# tviic2d6mddr register map
Vendor: Cypress Semiconductor; Series: tviic2d6mddr; File version: 1.0
CPU: CM7 r0p1, little endian, MPU, FPU, VTOR, 3 interrupt priority bits
Registers are 32-bit, read-write, reset 0x0 unless marked. A register's access mark holds for its fields unless they carry their own. Offsets are from the block's base; [hi:lo] are bit positions; lines under a group give offsets from that group; 'fields as' and 'values as' point back to an identical list.

## VIDEOSS0 (part 13 of 18) — Video and Graphics Subsystem IP
Base 0x40A00000
0x80000 VIDEOIO group — Video I/O Core
  0x24000 DISENG1 group — Display Engine
    0x1400 HISTOGRAM1 group — Histogram Unit
      0x08 BINCNTTHRESH — Bin counter threshold value.
        [28:0] BINCNT_THRESH — Bin counters below this threshold will be reported as 0. This threshold value will also affect the BINCNT_ACCU mode where 0 will be added for all bin counters below the threshold. (format is unsigned integer)
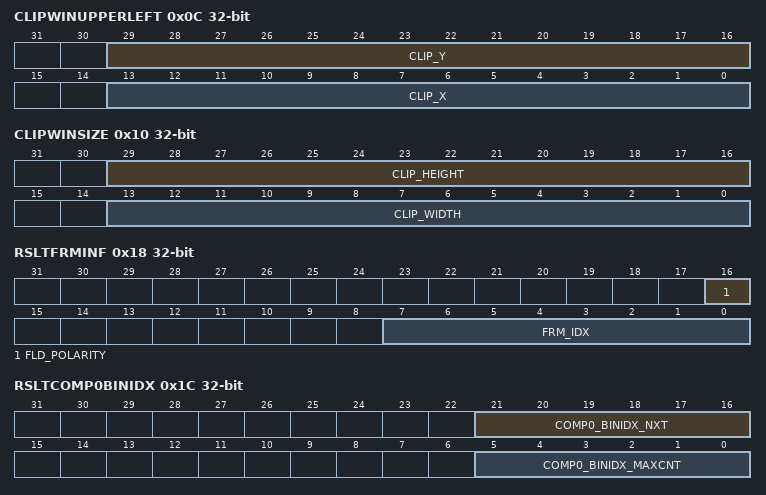
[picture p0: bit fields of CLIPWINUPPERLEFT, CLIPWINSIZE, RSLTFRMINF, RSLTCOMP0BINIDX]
      0x0C CLIPWINUPPERLEFT — Coordinates of upper left corner of clip window.
        [29:16] CLIP_Y — Y coordinate of upper left corner of clip window. (format is unsigned integer)
        [13:0] CLIP_X — X coordinate of upper left corner of clip window. (format is unsigned integer)
      0x10 CLIPWINSIZE — Dimensions of clip window.
        [29:16] CLIP_HEIGHT — Height of clip window, given minus one. (format is unsigned integer)
        [13:0] CLIP_WIDTH — Width of clip window, given minus one. (format is unsigned integer)
      0x14 RSLTRDY ro — Measurement result status.
        [0] RSLT_RDY — A one indicates that measurement results (in registers Rslt...) are valid and can be read. (format is unsigned integer)
      0x18 RSLTFRMINF ro — Additional information on the measurement results.
        [16] FLD_POLARITY — Returns field polarity of the measured frame. This read value of this field is undefined in display stream context; use in storage, content or safety stream context only. (format is unsigned integer)
        [7:0] FRM_IDX — Each frame passing the histogram unit gets an index, which is the value of a wrapped around counter, which counts the frames independent from how the histogram unit is configured. The index of the frame of the ongoing readout can be read here. In display stream context, if the display operation ends (framegen is switched off and sequence complete occurs) this frame index is reset to 0. (format is unsigned integer)
      0x1C RSLTCOMP0BINIDX ro — Results of frame measurement for component 0.
        [21:16] COMP0_BINIDX_NXT — Do not use this filed. The index of the bin, that will be next accessed by register RsltComp0Bincnt. In the case of RGB pixels, component0 means the red value, in the case of YUV pixels, component 0 means the Y value. If luma/luminance calculation is switched on by field lum_mode component0 is the calculated luma/luminance. (format is unsigned integer)
        [5:0] COMP0_BINIDX_MAXCNT — The index of the bin of the component 0 histogram, which contains the highest counter value, which were read until now for the ongoing readout. In the case of RGB pixels, component 0 means the red value, in the case of YUV pixels, component0 means the Y value. If luma/luminance calculation is switched on by field lum_mode component0 is the calculated luma/luminance. (format is unsigned integer)
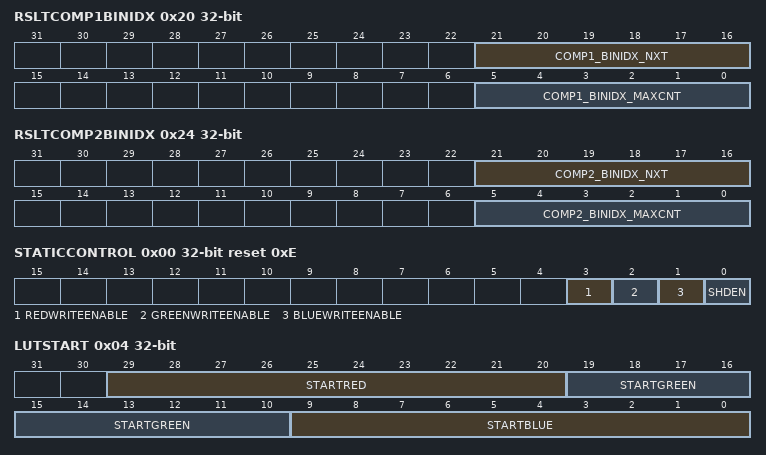
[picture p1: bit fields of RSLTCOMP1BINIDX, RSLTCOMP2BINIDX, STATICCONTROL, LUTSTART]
      0x20 RSLTCOMP1BINIDX ro — Results of frame measurement for component 1.
        [21:16] COMP1_BINIDX_NXT — The index of the bin, that will be next accessed by register RsltComp1Bincnt. In the case of RGB pixels, component 1 means the green value. In the case of YUV pixels, component 1 means the Cb value. (format is unsigned integer)
        [5:0] COMP1_BINIDX_MAXCNT — The index of the bin of the component 1 histogram, which contains the highest counter value, which were read until now for the ongoing readout. In the case of RGB pixels, component 1 means the green value. In the case of YUV pixels, component 1 means the Cb value. (format is unsigned integer)
      0x24 RSLTCOMP2BINIDX ro — Results of frame measurement for component 2.
        [21:16] COMP2_BINIDX_NXT — The index of the bin, that will be next accessed by register RsltComp2Bincnt. In the case of RGB pixels, component 2 means the blue value. In the case of YUV pixels, component 2 means the Cr value. (format is unsigned integer)
        [5:0] COMP2_BINIDX_MAXCNT — The index of the bin of the component 2 histogram, which contains the highest counter value, which were read until now for the ongoing readout. In the case of RGB pixels, component 2 means the blue value. In the case of YUV pixels, component 2 means the Cr value. (format is unsigned integer)
      0x28 RSLTCOMP0SUM ro — Sum of all component 0 values.
        [31:0] COMP0_SUM — Sum of all component 0 values. In the case of RGB pixels, component 0 means the red value, in the case of YUV pixels, component 0 means the Y value. If luma/luminance calculation is switched on by field lum_mode, component 0 is the calculated luma/luminance. If the read value is 0xFFFFFFFF a counter overflow has occurred and the read value should not be used (this can only happen for frame dimensions beyond 2^12 * 2^12). (format is unsigned integer)
      0x2C RSLTCOMP1SUM ro — Sum of all component 1 values.
        [31:0] COMP1_SUM — Sum of all component 1 values. In the case of RGB pixels, component 1 means the green value. In the case of YUV pixels, component 1 means the Cb value. If the read value is 0xFFFFFFFF a counter overflow has occurred and the read value should not be used (this can only happen for frame dimensions beyond 2^12 * 2^12). (format is unsigned integer)
      0x30 RSLTCOMP2SUM ro — Sum of all component 2 values.
        [31:0] COMP2_SUM — Sum of all component 2 values. In the case of RGB pixels, component 2 means the blue value. In the case of YUV pixels, component 2 means the Cr value. If the read value is 0xFFFFFFFF a counter overflow has occurred and the read value should not be used (this can only happen for frame dimensions beyond 2^12 * 2^12). (format is unsigned integer)
      0x34 RSLTCOMP0BINCNT ro — Bin counters of component 0 histogram. This register do NOT support debugger access followed by software access (they clear on read)
        [28:0] COMP0_BINCNT — Counter of current bin number in component 0 histogram. In the case of RGB pixels, component 0 means the red value, in the case of YUV pixels, component 0 means the Y value. (format is unsigned integer)
      0x38 RSLTCOMP1BINCNT ro — Bin counters of component 1 histogram. This register do NOT support debugger access followed by software access (they clear on read)
        [28:0] COMP1_BINCNT — Counter of current bin number in component 1 histogram. In the case of RGB pixels, component 1 means the green value. In the case of YUV pixels, component 1 means the Cb value. (format is unsigned integer)
      0x3C RSLTCOMP2BINCNT ro — Bin counters of component 2 histogram. This register do NOT support debugger access followed by software access (they clear on read)
        [28:0] COMP2_BINCNT — Counter of current bin index in component 2 histogram. In the case of RGB pixels, component 2 means the blue value. In the case of YUV pixels, component 2 means the Cb value. (format is unsigned integer)
      0x40 FRMSTRTTRIG wo reset not defined — Triggers for loading shadow registers and starting measurement with next input frame.
        [0] MSRMNT_STRT_TRIG — Writing value 1 into this field initiates the measurement of the next frame. (format is unsigned integer)
    0x1800 GAMMACOR21 group — Gamma Correction Unit 2
      0x00 STATICCONTROL reset 0xE — Static control settings.
        [3] REDWRITEENABLE — Write enable for the red color sampling point entries.
        [2] GREENWRITEENABLE — Write enable for the green color sampling point entries.
        [1] BLUEWRITEENABLE — Write enable for the blue color sampling point entries.
        [0] SHDEN — Enables shadowing of all RWS type registers (0=write_through, 1=shadowed).
      0x04 LUTSTART wo — Start values for look-up table programming.
        [29:20] STARTRED — Start value for red or luma (Y) channel. (format is unsigned integer)
        [19:10] STARTGREEN — Start value for green or chroma (U) channel. (format is unsigned integer)
        [9:0] STARTBLUE — Start value for blue or chroma (V) channel. (format is unsigned integer)
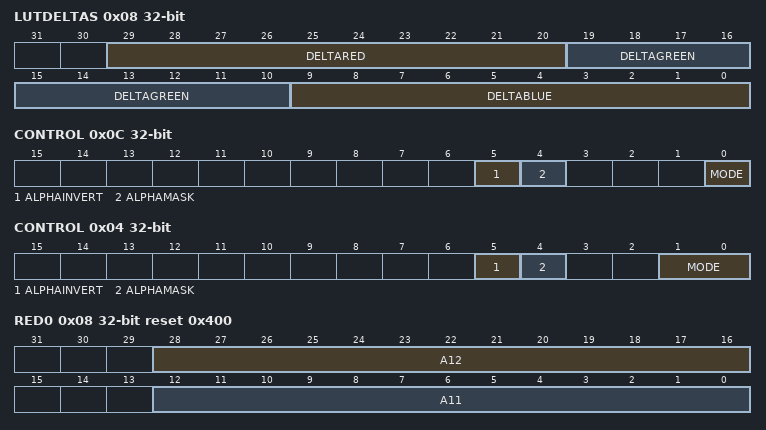
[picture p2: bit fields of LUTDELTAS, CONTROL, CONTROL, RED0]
      0x08 LUTDELTAS wo reset not defined — Delta values for look-up table programming.
        [29:20] DELTARED — Delta value for red or luma (Y) channel. (format is signed integer)
        [19:10] DELTAGREEN — Delta value for green or chroma (U) channel. (format is signed integer)
        [9:0] DELTABLUE — Delta value for blue or chroma (V) channel. (format is signed integer)
      0x0C CONTROL — Dynamic control settings.
        [5] ALPHAINVERT — Value 1 inverts the effect of the alpha mask mode when enabled (pixels with alpha value greater or equal 0.5 are by-passed).
        [4] ALPHAMASK — Value 1 enables the alpha mask mode. In this mode all pixels with an alpha value smaller than 0.5 are by-passed unchanged.
        [0] MODE — Operation mode for gamma correction unit
          0=NEUTRAL (Module in neutral mode, input data is bypassed to the output.); 1=GAMMACOR (Module in gamma correction mode.)
    0x1C00 MATRIX1 group — Color Matrix
      0x00 STATICCONTROL — Color Matrix static control register
        [0] SHDEN — Enables shadowing of all RWS type registers (0=write_through, 1=shadowed).
      0x04 CONTROL — Color Matrix control register
        [5] ALPHAINVERT — Value 1 inverts the effect of the alpha mask mode when enabled (pixels with alpha value greater or equal 0.5 are by-passed).
        [4] ALPHAMASK — Value 1 enables the alpha mask mode. In this mode all pixels with an alpha value smaller than 0.5 are by-passed unchanged.
        [1:0] MODE — Operation mode for color matrix
          0=NEUTRAL (Module in neutral mode, input data is bypassed); 1=MATRIX (Module in matrix mode, input data is multiplied with matrix values); 2=PREMUL (Module in alpha pre-multiplication mode, input color is multiplied with input alpha); 3=RSVD (N/A)
      0x08 RED0 reset 0x400 — Matrix values for calculation of the red output value.
        [28:16] A12 — Value for green input. (format is signed fix-point 3.10)
        [12:0] A11 — Value for red input. (format is signed fix-point 3.10)
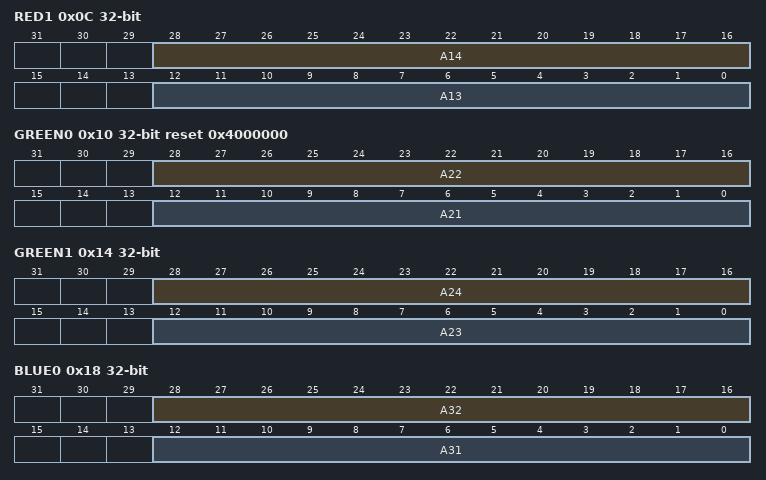
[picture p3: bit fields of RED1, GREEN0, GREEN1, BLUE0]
      0x0C RED1 — Matrix values for calculation of the red output value.
        [28:16] A14 — Value for alpha input. (format is signed fix-point 3.10)
        [12:0] A13 — Value for blue input. (format is signed fix-point 3.10)
      0x10 GREEN0 reset 0x4000000 — Matrix values for calculation of the green output value.
        [28:16] A22 — Value for green input. (format is signed fix-point 3.10)
        [12:0] A21 — Value for red input. (format is signed fix-point 3.10)
      0x14 GREEN1 — Matrix values for calculation of the green output value.
        [28:16] A24 — Value for alpha input. (format is signed fix-point 3.10)
        [12:0] A23 — Value for blue input. (format is signed fix-point 3.10)
      0x18 BLUE0 — Matrix values for calculation of the blue output value.
        [28:16] A32 — Value for green input. (format is signed fix-point 3.10)
        [12:0] A31 — Value for red input. (format is signed fix-point 3.10)
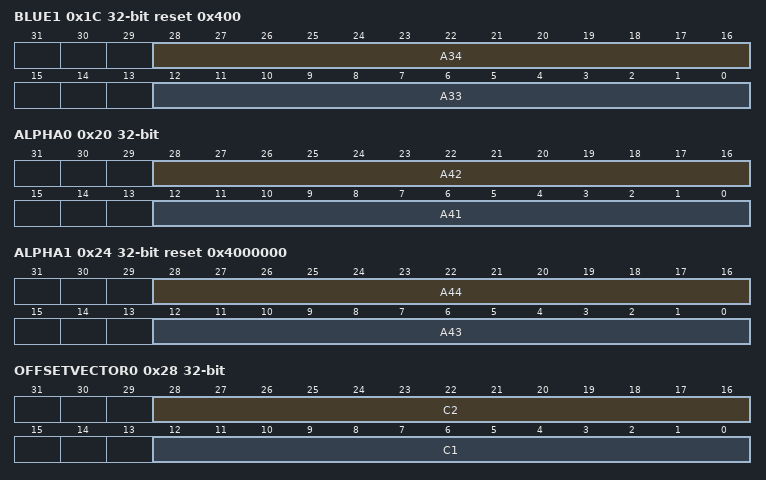
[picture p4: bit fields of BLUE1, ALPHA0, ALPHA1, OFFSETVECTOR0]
      0x1C BLUE1 reset 0x400 — Matrix values for calculation of the blue output value.
        [28:16] A34 — Value for alpha input. (format is signed fix-point 3.10)
        [12:0] A33 — Value for blue input. (format is signed fix-point 3.10)
      0x20 ALPHA0 — Matrix values for calculation of the alpha output value.
        [28:16] A42 — Value for green input. (format is signed fix-point 3.10)
        [12:0] A41 — Value for red input. (format is signed fix-point 3.10)
      0x24 ALPHA1 reset 0x4000000 — Matrix values for calculation of the alpha output value.
        [28:16] A44 — Value for alpha input. (format is signed fix-point 3.10)
        [12:0] A43 — Value for blue input. (format is signed fix-point 3.10)
      0x28 OFFSETVECTOR0 — Offset vectors for red and green output.
        [28:16] C2 — Green output offset. (format is signed integer)
        [12:0] C1 — Red output offset. (format is signed integer)
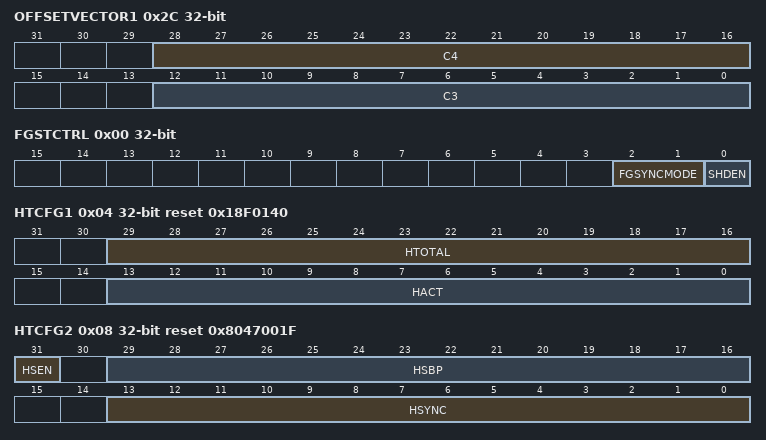
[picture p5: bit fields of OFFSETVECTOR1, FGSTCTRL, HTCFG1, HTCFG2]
      0x2C OFFSETVECTOR1 — Offset vectors for blue and alpha output.
        [28:16] C4 — Alpha output offset. Note that the 8-bit alpha input is up-scaled to 10-bit, before the matrix and this offset is applied, and down-scaled to 8-bit for output afterwards. (format is signed integer)
        [12:0] C3 — Blue output offset. (format is signed integer)
    0x2000 FRAMEGEN1 group — Frame Generator
      0x00 FGSTCTRL — FrameGen Static Control Register
        [2:1] FGSYNCMODE — Determines the operating mode of the framegen unit for side-by-side synchronization. The framegen unit programmed as master generates synchronization pulses. The framegen units programmed as slaves are synchronized to the master unit. There must be only one framegen unit programmed acting as master.
          0=OFF (No side-by-side synchronization.); 1=MASTER (Framegen is master.); 2=SLAVE_CYC (Framegen is slave. Runs in cyclic synchronization mode.); 3=SLAVE_ONCE (Framegen is slave. Runs in one time synchronization mode.)
        [0] SHDEN — Enables shadowing for RWS type configuration fields. Otherwise shadow registers are immediately updated when written.
      0x04 HTCFG1 reset 0x18F0140 — FrameGen Horizontal Timing Config Register 1
        [29:16] HTOTAL — Total horizontal size of frame in pixels. (Set value +1 is the total horizontal size of frame) Htotal shall be greater or equal than Hact + Hsbp. Note1: Valid setup for horizontal video timing contains parameters Hact, Htotal, Hsbp and, if enabled, Hsync. Note2: If SRAdj==1 then Htotal[0] shall be equal the value of SREven (for sec. channel only).
        [13:0] HACT — Horizontal size of active display area in pixels. Hact shall be greater or equal than 4. Note: Valid setup for horizontal video timing contains parameters Hact, Htotal, Hsbp and, if enabled, Hsync.
      0x08 HTCFG2 reset 0x8047001F — FrameGen Horizontal Timing Config Register 2
        [31] HSEN — Enables generation of HSYNC pulse.
        [29:16] HSBP — Width of HSYNC pulse plus width of horizontal back porch in pixels. (Set value +1 is the width of HSYNC pulse plus width of horizontal back porch) Hsbp shall be greater or equal than Hsync. Note: Valid setup for horizontal video timing contains parameters Hact, Htotal, Hsbp and, if enabled, Hsync.
        [13:0] HSYNC — Width of HSYNC pulse in pixels. (Set value +1 is the width of HSYNC pulse) HSYNC is of zero width if HsEn==0. Note: Valid setup for horizontal video timing contains parameters Hact, Htotal, Hsbp and, if enabled, Hsync.
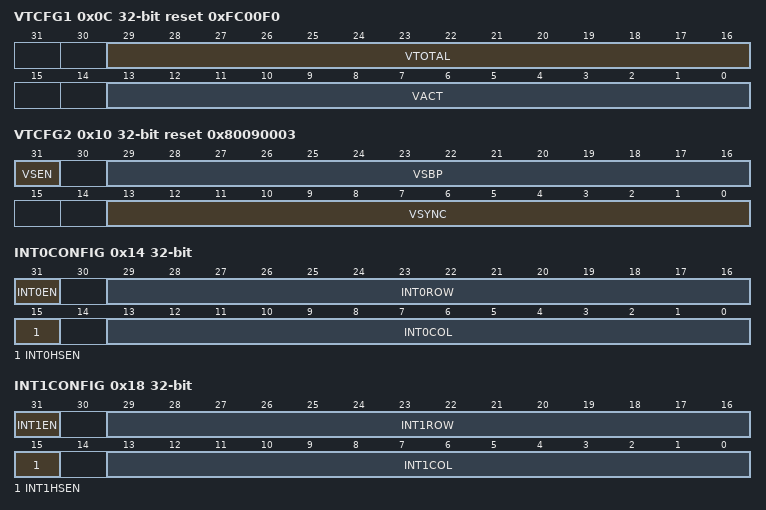
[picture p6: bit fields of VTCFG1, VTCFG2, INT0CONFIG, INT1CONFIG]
      0x0C VTCFG1 reset 0xFC00F0 — FrameGen Vertical Timing Config Register 1
        [29:16] VTOTAL — Total vertical size of frame in lines. (Set value +1 is the total vertical size of frame) Vtotal shall be greater or equal than Vact + Vsbp. Note: Valid setup for vertical video timing contains parameters Vact, Vtotal, Vsbp and, if enabled, Vsync.
        [13:0] VACT — Vertical size of active display area in lines. Vact shall be greater or equal than 4. Note: Valid setup for vertical video timing contains parameters Vact, Vtotal, Vsbp and, if enabled, Vsync.
      0x10 VTCFG2 reset 0x80090003 — FrameGen Vertical Timing Config Register 2
        [31] VSEN — Enables generation of VSYNC pulse.
        [29:16] VSBP — Width of VSYNC pulse plus width of vertical back porch in lines. (Set value +1 is the width of VSYNC pulse plus width of vertical back porch) Vsbp shall be greater or equal than Vsync. Note: Valid setup for vertical video timing contains parameters Vact, Vtotal, Vsbp and, if enabled, Vsync.
        [13:0] VSYNC — Width of VSYNC pulse in lines. (Set value +1 is the width of VSYNC pulse) VSYNC is of zero width if VsEn==0. Note: Valid setup for vertical video timing contains parameters Vact, Vtotal, Vsbp and, if enabled, Vsync.
      0x14 INT0CONFIG — Coordinates of the trigger point for generation of the Int0 interrupt signal
        [31] INT0EN — Enables Int0.
        [29:16] INT0ROW — Specifies on which row of the display raster the Int0 signal is triggered (1 .. Int0Row .. VTOTAL). Adaptive display timing must be taken into account when defining Int0Row (1 .. Int0Row .. VTOTAL_MIN).
        [15] INT0HSEN — When enabled, Int0Row setting is ignored so that the interrupt occurs every line at position given by Int0Col.
        [13:0] INT0COL — Specifies on which column of the display raster the Int0 signal is triggered (1 .. Int0Col .. HTOTAL). Adaptive display timing must be taken into account when defining Int0Col (1 .. Int0Col .. HTOTAL_MIN).
      0x18 INT1CONFIG — Coordinates of the trigger point for generation of the Int1 interrupt signal
        [31] INT1EN — Enables Int1 (irq[1]).
        [29:16] INT1ROW — Specifies on which row of the display raster the Int1 signal is triggered (1 .. Int1Row .. VTOTAL). Adaptive display timing must be taken into account when defining Int1Row (1 .. Int1Row .. VTOTAL_MIN).
        [15] INT1HSEN — When enabled, Int1Row setting is ignored so that the interrupt occurs every line at position given by Int1Col.
        [13:0] INT1COL — Specifies on which column of the display raster the Int1 signal is triggered (1 .. Int1Col .. HTOTAL). Adaptive display timing must be taken into account when defining Int1Col (1 .. Int1Col .. HTOTAL_MIN).
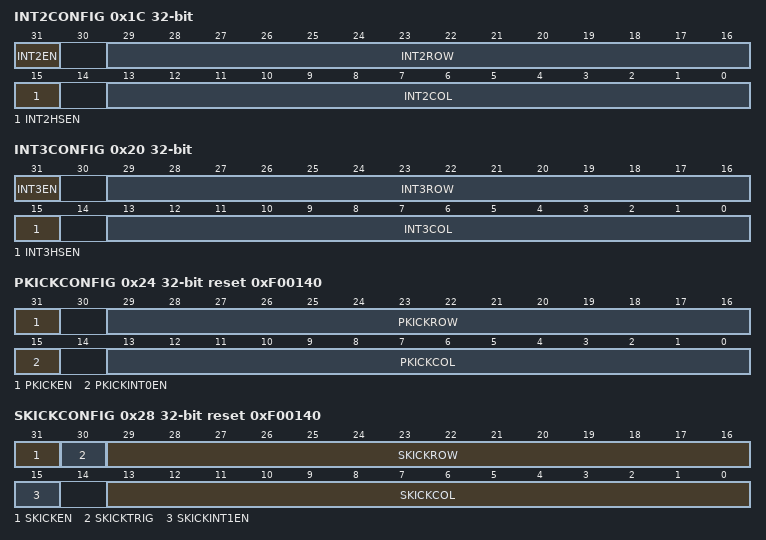
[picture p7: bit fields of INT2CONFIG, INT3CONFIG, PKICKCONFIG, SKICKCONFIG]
      0x1C INT2CONFIG — Coordinates of the trigger point for generation of the Int2 interrupt signal
        [31] INT2EN — Enables Int2.
        [29:16] INT2ROW — Specifies on which row of the display raster the Int2 signal is triggered (1 .. Int2Row .. VTOTAL). Adaptive display timing must be taken into account when defining Int2Row (1 .. Int2Row .. VTOTAL_MIN).
        [15] INT2HSEN — When enabled, Int2Row setting is ignored so that the interrupt occurs every line at position given by Int2Col.
        [13:0] INT2COL — Specifies on which column of the display raster the Int2 signal is triggered (1 .. Int2Col .. HTOTAL). Adaptive display timing must be taken into account when defining Int2Col (1 .. Int2Col .. HTOTAL_MIN).
      0x20 INT3CONFIG — Coordinates of the trigger point for generation of the Int3 interrupt signal
        [31] INT3EN — Enables Int3.
        [29:16] INT3ROW — Specifies on which row of the display raster the Int3 signal is triggered (1 .. Int3Row .. VTOTAL). Adaptive display timing must be taken into account when defining Int3Row (1 .. Int3Row .. VTOTAL_MIN).
        [15] INT3HSEN — When enabled, Int3Row setting is ignored so that the interrupt occurs every line at position given by Int3Col.
        [13:0] INT3COL — Specifies on which column of the display raster the Int3 signal is triggered (1 .. Int3Col .. HTOTAL). Adaptive display timing must be taken into account when defining Int3Col (1 .. Int3Col .. HTOTAL_MIN).
      0x24 PKICKCONFIG reset 0xF00140 — Coordinates of the trigger point for generation of the primary kick signal
        [31] PKICKEN — Enables pkick signal.
        [29:16] PKICKROW — Specifies on which row of the display raster the pkick signal is triggered (1 .. PKickRow .. VTOTAL). Adaptive display timing must be taken into account when defining PKickRow (1 .. PKickRow .. VTOTAL_MIN).
        [15] PKICKINT0EN — If enabled, maps the primary kick signal (pkick) on the interrupt pin int0. Overrides int0en.
        [13:0] PKICKCOL — Specifies on which column of the display raster the pkick signal is triggered (1 .. PKickCol .. HTOTAL). Adaptive display timing must be taken into account when defining PKickCol (1 .. PKickCol .. HTOTAL_MIN).
      0x28 SKICKCONFIG reset 0xF00140 — Coordinates of the trigger point for generation of the secondary kick signal
        [31] SKICKEN — Enables generation of internal skick signal.
        [30] SKICKTRIG — Select source for skick generation.
          0=INTERNAL (Use internal skick signal, trigger point defined by SKickRow and SKickCol.); 1=EXTERNAL (Use external skick input as trigger.)
        [29:16] SKICKROW — Specifies on which row of the display raster the skick signal is triggered (1 .. SKickRow .. VTOTAL). Adaptive display timing must be taken into account when defining SKickRow (1 .. SKickRow .. VTOTAL_MIN).
        [15] SKICKINT1EN — If enabled, maps the secondary kick signal (skick) on the interrupt pin int1. Overrides int1en.
        [13:0] SKICKCOL — Specifies on which column of the display raster the skick signal is triggered (1 .. SKickCol .. HTOTAL). Adaptive display timing must be taken into account when defining SKickCol (1 .. SKickCol .. HTOTAL_MIN).
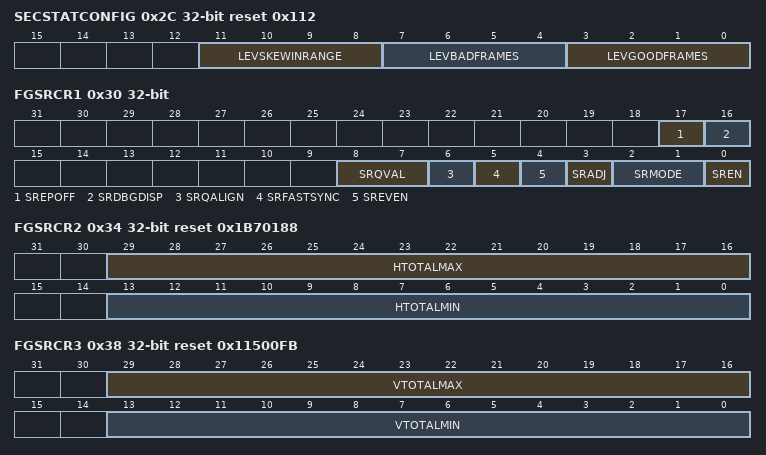
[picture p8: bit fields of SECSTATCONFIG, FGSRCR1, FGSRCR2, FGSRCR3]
      0x2C SECSTATCONFIG reset 0x112 — Configuration register for controlling the behavior of the SecSyncStat field in the FgSecChStat register.
        [11:8] LEVSKEWINRANGE — Number of continuous frames the measured skew value shall be within the range defined by SyncRangeLow and SyncRangeHigh. If this condition is true, additionally LevGoodFrames valid frames must be processed before the status line of the sec. channel and the SecSyncStat status field goes to 1 indicating synchronized status. Value of 0 is not allowed.
        [7:4] LEVBADFRAMES — Not used.
        [3:0] LEVGOODFRAMES — Number of continuous correct frames that must be processed before SecSyncStat field goes 1 (in sync). Value of 0 is not allowed.
      0x30 FGSRCR1 — FrameGen Skew Regulation Control Register 1.
        [17] SREPOFF — Disables the skew Extrapolation in blanking.
        [16] SRDBGDISP — If enabled, the pixels are displayed that are read from FIFO when secondary channel is not in sync yet. Otherwise constant color is displayed in unsynchronized state.
        [8:7] SRQVAL — If SRQAlign is enabled, this field determines the fixed value of the two LSB bits of HTOTAL. Note: This has impact on the settings for Htotal, HtotalMin and HtotalMax.
          0=ZERO (Fixed two LSB values of HTOTAL are 0b00.); 1=ONE (Fixed two LSB values of HTOTAL are 0b01.); 2=TWO (Fixed two LSB values of HTOTAL are 0b10.); 3=THREE (Fixed two LSB values of HTOTAL are 0b11.)
        [6] SRQALIGN — Enables alignment of HTOTAL to be a multiple of 4. Overrides SREven field. Program field SRQVal for the desired value of the two LSB bits of HTOTAL.
        [5] SRFASTSYNC — Fast Synchronization Mode. Frame Generator is started synchronized to frame timing on secondary channel when switching FgEn from 0 to 1. This allows fast locking of skew regulation.
        [4] SREVEN — Total line length HTOTAL is even when SRAdj is enabled. Note: This has impact on the settings for Htotal, HtotalMin and HtotalMax.
        [3] SRADJ — Enables line length adjustment for HTOTAL. If SRQAlign=0, SREven determines whether HTOTAL has odd (SREven=0) or even (SrEven=1) number of pixels. If SRQAlign=1, SRQVal determines the value of the two LSB bits of HTOTAL.
        [2:1] SRMODE — Skew Control Operating Mode.
          0=OFF (Skew Regulation is off.); 1=HREG (Horizontal regulation enabled.); 2=VREG (Vertical regulation enabled.); 3=BOTH (Both regulation modes are enabled.)
        [0] SREN — If enabled, skew control for secondary channel is active. If disabled, skew control for secondary channel is in fetch mode. Fetch mode: secondary channel fetches frames and can intentionally produce a backstall via setting sbusy signal to active. This mode is intended to fetch frames from memory via a stallable pipeline, like the primary interface. No timing adaption of frames takes place in this mode.
      0x34 FGSRCR2 reset 0x1B70188 — FrameGen Skew Regulation Control Register 2
        [29:16] HTOTALMAX — Maximum value of htotal when horizontal regulation is enabled. (Set value +1 is the maximum value of htotal) HTotalMax must be greater or equal Htotal. Note: If SRAdj==1 then HtotalMax[0] shall be equal to the value of SREven.
        [13:0] HTOTALMIN — Minimum value of htotal when horizontal regulation is enabled. (Set value +1 is the minimum value of htotal, must be greater or equal Hsbp + Hactive) HTotalMin must be smaller or equal Htotal. Note: If SRAdj==1 then HtotalMin[0] shall be equal to the value of SREven.
      0x38 FGSRCR3 reset 0x11500FB — FrameGen Skew Regulation Control Register 3
        [29:16] VTOTALMAX — Maximum value of vtotal when vertical regulation is enabled. (Set value +1 is the maximum value of vtotal)
        [13:0] VTOTALMIN — Minimum value of vtotal when vertical regulation is enabled. (Set value +1 is the minimum value of vtotal, must be greater or equal Vsbp + Vactive + 1)
      0x3C FGSRCR4 reset 0xC8 — FrameGen Skew Regulation Control Register 4
        [28:0] TARGETSKEW — Horizontal target skew value for horizontal and vertical skew regulation (signed value). (format is signed integer)
      0x40 FGSRCR5 — FrameGen Skew Regulation Control Register 5
        [28:0] SYNCRANGELOW — Sync range of horizontal and vertical skew regulation. Lower value (signed value). If skew stays within programmed sync range, frame status is assumed synchronized. (format is signed integer)
      0x44 FGSRCR6 reset 0x190 — FrameGen Skew Regulation Control Register 6
        [28:0] SYNCRANGEHIGH — Sync range of horizontal and vertical skew regulation. Upper value (signed value). If skew stays within programmed sync range, frame status is assumed synchronized. (format is signed integer)
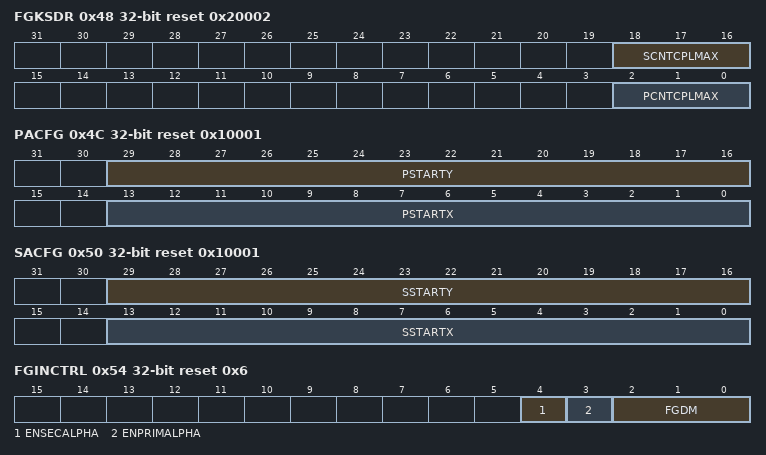
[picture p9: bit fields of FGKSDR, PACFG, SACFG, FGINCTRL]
      0x48 FGKSDR reset 0x20002 — FrameGen Kick System Debug Register
        [18:16] SCNTCPLMAX — Maximum Value for spendcnt_cpl_s complementary secondary kick counter. Do not change!
        [2:0] PCNTCPLMAX — Maximum Value for ppendcnt_cpl_s complementary primary kick counter. Do not change!
      0x4C PACFG reset 0x10001 — FrameGen Primary Area Config Register 1 (shadowed)
        [29:16] PSTARTY — Primary screen upper left corner, y component. Counts from 1. Pstarty = 0 is not allowed. Primary screen shall not overlap the last column/ last row of the total frame defined by Htotal/ Vtotal.
        [13:0] PSTARTX — Primary screen upper left corner, x component. Counts from 1. Pstartx = 0 is not allowed. Primary screen shall not overlap the last column/ last row of the total frame defined by Htotal/ Vtotal.
      0x50 SACFG reset 0x10001 — FrameGen Secondary Area Config Register 1 (shadowed)
        [29:16] SSTARTY — Secondary screen upper left corner, y component. Counts from 1 . Sstarty = 0 is not allowed. Secondary screen shall not overlap the last column/ last row of the total frame defined by Htotal/ Vtotal. When skew regulation feature is enabled, the secondary screen shall not overlap the active display area defined by Hact and Vact.
        [13:0] SSTARTX — Secondary screen upper left corner, x component. Counts from 1 . Sstartx = 0 is not allowed. Secondary screen shall not overlap the last column/ last row of the total frame defined by Htotal/ Vtotal. When skew regulation feature is enabled, the secondary screen shall not overlap the active display area defined by Hact and Vact.
      0x54 FGINCTRL reset 0x6 — FrameGen Input Control Register (shadowed)
        [4] ENSECALPHA — When enabled, alpha plane of secondary channel is considered for screen composition. If the alpha component of the current pixel is 255, this pixel is opaque. Otherwise this pixel is transparent. Setting this field to 1 has no effect, when FgDm == BLEND.
        [3] ENPRIMALPHA — When enabled, alpha plane of primary channel is considered for screen composition. If the alpha component of the current pixel is 255, this pixel is opaque. Otherwise this pixel is transparent. Setting this field to 1 has no effect, when FgDm == BLEND.
        [2:0] FGDM — Frame Generator Display Mode.
          0=BLACK (Black color background is shown on the whole screen area.); 1=CONSTCOL (Programmable constant color is shown in the active area and black color in the blanking area.); 2=PRIM (Primary input only is shown.); 3=SEC (Secondary input only is shown.); 4=PRIM_ON_TOP (Both inputs overlaid with primary on top.); 5=SEC_ON_TOP (Both inputs overlaid with secondary on top.); 6=TEST (White color background with test pattern is shown in the active area and black color in the blanking area.); 7=BLEND (Blending of the mode PRIM with the mode SEC.)
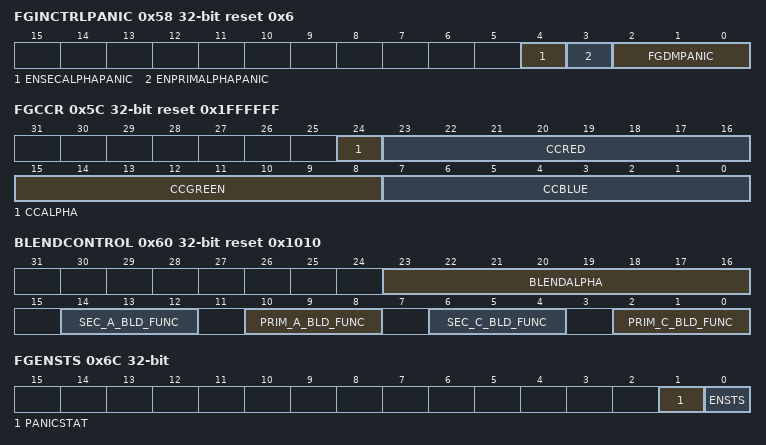
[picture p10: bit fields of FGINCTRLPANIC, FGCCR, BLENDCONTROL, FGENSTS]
      0x58 FGINCTRLPANIC reset 0x6 — FrameGen Input Control Panic Register (shadowed)
        [4] ENSECALPHAPANIC — When enabled, alpha plane of secondary channel is considered for screen composition. If the alpha component of the current pixel is 255, this pixel is opaque. Otherwise this pixel is transparent. Setting this field to 1 has no effect, when FgDmPanic == BLEND.
        [3] ENPRIMALPHAPANIC — When enabled, alpha plane of primary channel is considered for screen composition. If the alpha component of the current pixel is 255, this pixel is opaque. Otherwise this pixel is transparent. Setting this field to 1 has no effect, when FgDmPanic == BLEND.
        [2:0] FGDMPANIC — Frame Generator Display Mode.
          values as VIDEOIO.DISENG1.FRAMEGEN1.FGINCTRL.FGDM
      0x5C FGCCR reset 0x1FFFFFF — FrameGen Constant Color Register (shadowed)
        [24] CCALPHA — Constant color - alpha value. In case of blending the value of 1 will be extended to 0xff.
        [23:16] CCRED — Constant color - red component.
        [15:8] CCGREEN — Constant color - green component.
        [7:0] CCBLUE — Constant color - blue component.
      0x60 BLENDCONTROL reset 0x1010 — Options for blend operations. (shadowed)
        [23:16] BLENDALPHA — Constant alpha value, used for constant alpha blending
        [14:12] SEC_A_BLD_FUNC — Secondary (overlay) input alpha blending function
          0=ZERO (Aout = Ain * 0); 1=ONE (Aout = Ain * 1); 2=PRIM_ALPHA (Aout = Ain * ALPHA_prim); 3=ONE_MINUS_PRIM_ALPHA (Aout = Ain * (1 - ALPHA_prim)); 4=SEC_ALPHA (Aout = Ain * ALPHA_sec); 5=ONE_MINUS_SEC_ALPHA (Aout = Ain * (1 - ALPHA_sec)); 6=CONST_ALPHA (Aout = Ain * ALPHA_const); 7=ONE_MINUS_CONST_ALPHA (Aout = Ain * (1 - ALPHA_const))
        [10:8] PRIM_A_BLD_FUNC — Primary (background) input alpha blending function
          values as SEC_A_BLD_FUNC
        [6:4] SEC_C_BLD_FUNC — Secondary (overlay) input color blending function
          0=ZERO (Cout = Cin * 0); 1=ONE (Cout = Cin * 1); 2=PRIM_ALPHA (Cout = Cin * ALPHA_prim); 3=ONE_MINUS_PRIM_ALPHA (Cout = Cin * (1 - ALPHA_prim)); 4=SEC_ALPHA (Cout = Cin * ALPHA_sec); 5=ONE_MINUS_SEC_ALPHA (Cout = Cin * (1 - ALPHA_sec)); 6=CONST_ALPHA (Cout = Cin * ALPHA_const); 7=ONE_MINUS_CONST_ALPHA (Cout = Cin * (1 - ALPHA_const))
        [2:0] PRIM_C_BLD_FUNC — Primary (background) input color blending function
          values as SEC_C_BLD_FUNC
      0x64 FGENABLE — FrameGen Enable Register
        [0] FGEN — Frame Generator Enable. Note: For loading the shadow registers at start-up of FrameGen unit write the FgSlr.ShdTokGen field immediately before writing this field.
      0x68 FGSLR wo reset not defined — FrameGen Shadow Load Register
        [0] SHDTOKGEN — Generate shadow load token. Can be used to load shadow register in this and/or all subsequent units up to the next token end point.
      0x6C FGENSTS ro — FrameGen Enable Status Register
        [1] PANICSTAT — Current status of panic mode (0=normal operation mode, 1=panic mode; not locked).
        [0] ENSTS — Indicates the current operating mode of the frame generator. EnSts = 0 means frame generator is disabled. EnSts = 1 means frame generator is enabled. In contrast to the FgEn field of the FgEnable register this bit goes only 0 when all pending frames are processed.
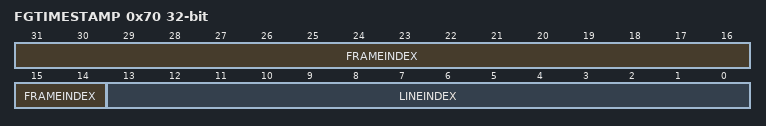
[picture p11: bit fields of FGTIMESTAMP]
      0x70 FGTIMESTAMP ro — Time stamp status.
        [31:14] FRAMEINDEX — Index of the output frame that is currently generated (starts with 0 after reset for first output frame). Wraps around to 0 when maximum value is reached.
        [13:0] LINEINDEX — Index of the output line that is currently generated (starts with 0 for first active output line).
